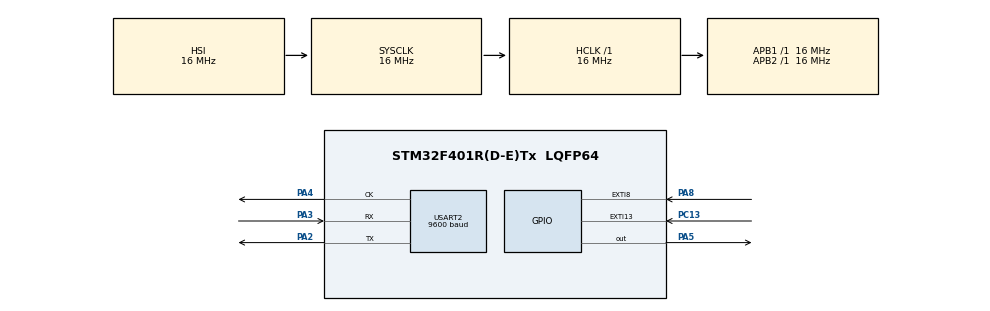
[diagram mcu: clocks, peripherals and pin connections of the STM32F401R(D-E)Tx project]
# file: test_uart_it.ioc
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Mcu.Family=STM32F4
Mcu.Name=STM32F401R(D-E)Tx
Mcu.Package=LQFP64
NVIC.EXTI15_10_IRQn=true\:0\:0\:false\:false\:true\:true\:true
NVIC.EXTI9_5_IRQn=true\:1\:0\:true\:false\:true\:true\:true
NVIC.PriorityGroup=NVIC_PRIORITYGROUP_4
NVIC.USART2_IRQn=true\:0\:0\:false\:false\:true\:true\:true
PA13.Mode=Serial_Wire
PA13.Signal=SYS_JTMS-SWDIO
PA14.Mode=Serial_Wire
PA14.Signal=SYS_JTCK-SWCLK
PA2.GPIO_PuPd=GPIO_PULLDOWN
PA2.Mode=Synchronous
PA2.Signal=USART2_TX
PA3.GPIO_PuPd=GPIO_PULLDOWN
PA3.Mode=Synchronous
PA3.Signal=USART2_RX
PA4.Mode=Synchronous
PA4.Signal=USART2_CK
PA5.Signal=GPIO_Output
PA8.GPIO_ModeDefaultEXTI=GPIO_MODE_IT_RISING
PA8.GPIO_PuPd=GPIO_PULLDOWN
PA8.Signal=GPXTI8
PC13-ANTI_TAMP.GPIO_ModeDefaultEXTI=GPIO_MODE_IT_FALLING
PC13-ANTI_TAMP.GPIO_PuPd=GPIO_PULLUP
PC13-ANTI_TAMP.Signal=GPXTI13
PH0\ -\ OSC_IN.Mode=HSE-External-Clock-Source
PH0\ -\ OSC_IN.Signal=RCC_OSC_IN
PH1\ -\ OSC_OUT.Mode=HSE-External-Clock-Source
PH1\ -\ OSC_OUT.Signal=RCC_OSC_OUT
ProjectManager.HeapSize=0x200
ProjectManager.StackSize=0x400
ProjectManager.TargetToolchain=STM32CubeIDE
RCC.AHBFreq_Value=16000000
RCC.APB1Freq_Value=16000000
RCC.APB2Freq_Value=16000000
RCC.CortexFreq_Value=16000000
RCC.HSE_VALUE=25000000
RCC.HSI_VALUE=16000000
RCC.LSE_VALUE=32768
RCC.SYSCLKFreq_VALUE=16000000
RCC.VCOOutputFreq_Value=192000000
USART2.BaudRate=9600
USART2.VirtualMode=VM_SYNC
board=custom

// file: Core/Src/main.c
/* USER CODE BEGIN Header */
/**
  ******************************************************************************
  * @file           : main.c
  * @brief          : Main program body
  ******************************************************************************
  * @attention
  *
  * <h2><center>&copy; Copyright (c) 2021 STMicroelectronics.
  * All rights reserved.</center></h2>
  *
  * This software component is licensed by ST under BSD 3-Clause license,
  * the "License"; You may not use this file except in compliance with the
  * License. You may obtain a copy of the License at:
  *                        opensource.org/licenses/BSD-3-Clause
  *
  ******************************************************************************
  */
/* USER CODE END Header */
#include "main.h"

USART_HandleTypeDef husart2;

void SystemClock_Config(void);
static void MX_GPIO_Init(void);
static void MX_USART2_Init(void);

int main(void)
{

  /* MCU Configuration--------------------------------------------------------*/

  /* Reset of all peripherals, Initializes the Flash interface and the Systick. */
  HAL_Init();

  /* Configure the system clock */
  SystemClock_Config();

  /* Initialize all configured peripherals */
  MX_GPIO_Init();
  MX_USART2_Init();
  /* USER CODE BEGIN 2 */
	uint8_t data[] = "querty";
	HAL_USART_Transmit_IT(&husart2, &data[0], 6);
  /* USER CODE END 2 */

  /* Infinite loop */
  while (1)
  {

  }
}

void SystemClock_Config(void)
{
  RCC_OscInitTypeDef RCC_OscInitStruct = {0};
  RCC_ClkInitTypeDef RCC_ClkInitStruct = {0};

  /** Configure the main internal regulator output voltage
  */
  __HAL_RCC_PWR_CLK_ENABLE();
  __HAL_PWR_VOLTAGESCALING_CONFIG(PWR_REGULATOR_VOLTAGE_SCALE2);
  /** Initializes the RCC Oscillators according to the specified parameters
  * in the RCC_OscInitTypeDef structure.
  */
  RCC_OscInitStruct.OscillatorType = RCC_OSCILLATORTYPE_HSI;
  RCC_OscInitStruct.HSIState = RCC_HSI_ON;
  RCC_OscInitStruct.HSICalibrationValue = RCC_HSICALIBRATION_DEFAULT;
  RCC_OscInitStruct.PLL.PLLState = RCC_PLL_NONE;
  if (HAL_RCC_OscConfig(&RCC_OscInitStruct) != HAL_OK)
  {
    Error_Handler();
  }
  /** Initializes the CPU, AHB and APB buses clocks
  */
  RCC_ClkInitStruct.ClockType = RCC_CLOCKTYPE_HCLK|RCC_CLOCKTYPE_SYSCLK
                              |RCC_CLOCKTYPE_PCLK1|RCC_CLOCKTYPE_PCLK2;
  RCC_ClkInitStruct.SYSCLKSource = RCC_SYSCLKSOURCE_HSI;
  RCC_ClkInitStruct.AHBCLKDivider = RCC_SYSCLK_DIV1;
  RCC_ClkInitStruct.APB1CLKDivider = RCC_HCLK_DIV1;
  RCC_ClkInitStruct.APB2CLKDivider = RCC_HCLK_DIV1;

  if (HAL_RCC_ClockConfig(&RCC_ClkInitStruct, FLASH_LATENCY_0) != HAL_OK)
  {
    Error_Handler();
  }
}

static void MX_USART2_Init(void)
{

  husart2.Instance = USART2;
  husart2.Init.BaudRate = 9600;
  husart2.Init.WordLength = USART_WORDLENGTH_8B;
  husart2.Init.StopBits = USART_STOPBITS_1;
  husart2.Init.Parity = USART_PARITY_NONE;
  husart2.Init.Mode = USART_MODE_TX_RX;
  husart2.Init.CLKPolarity = USART_POLARITY_LOW;
  husart2.Init.CLKPhase = USART_PHASE_1EDGE;
  husart2.Init.CLKLastBit = USART_LASTBIT_DISABLE;
  if (HAL_USART_Init(&husart2) != HAL_OK)
  {
    Error_Handler();
  }

}

static void MX_GPIO_Init(void)
{
  GPIO_InitTypeDef GPIO_InitStruct = {0};

  /* GPIO Ports Clock Enable */
  __HAL_RCC_GPIOC_CLK_ENABLE();
  __HAL_RCC_GPIOH_CLK_ENABLE();
  __HAL_RCC_GPIOA_CLK_ENABLE();

  /*Configure GPIO pin Output Level */
  HAL_GPIO_WritePin(GPIOA, GPIO_PIN_5, GPIO_PIN_RESET);

  /*Configure GPIO pin : PC13 */
  GPIO_InitStruct.Pin = GPIO_PIN_13;
  GPIO_InitStruct.Mode = GPIO_MODE_IT_FALLING;
  GPIO_InitStruct.Pull = GPIO_PULLUP;
  HAL_GPIO_Init(GPIOC, &GPIO_InitStruct);

  /*Configure GPIO pin : PA5 */
  GPIO_InitStruct.Pin = GPIO_PIN_5;
  GPIO_InitStruct.Mode = GPIO_MODE_OUTPUT_PP;
  GPIO_InitStruct.Pull = GPIO_NOPULL;
  GPIO_InitStruct.Speed = GPIO_SPEED_FREQ_LOW;
  HAL_GPIO_Init(GPIOA, &GPIO_InitStruct);

  /*Configure GPIO pin : PA8 */
  GPIO_InitStruct.Pin = GPIO_PIN_8;
  GPIO_InitStruct.Mode = GPIO_MODE_IT_RISING;
  GPIO_InitStruct.Pull = GPIO_PULLDOWN;
  HAL_GPIO_Init(GPIOA, &GPIO_InitStruct);

  /* EXTI interrupt init*/
  HAL_NVIC_SetPriority(EXTI9_5_IRQn, 1, 0);
  HAL_NVIC_EnableIRQ(EXTI9_5_IRQn);

  HAL_NVIC_SetPriority(EXTI15_10_IRQn, 0, 0);
  HAL_NVIC_EnableIRQ(EXTI15_10_IRQn);

}

void Error_Handler(void)
{
  __disable_irq();
  while (1)
  {
  }
}

/************************ (C) COPYRIGHT STMicroelectronics *****END OF FILE****/
